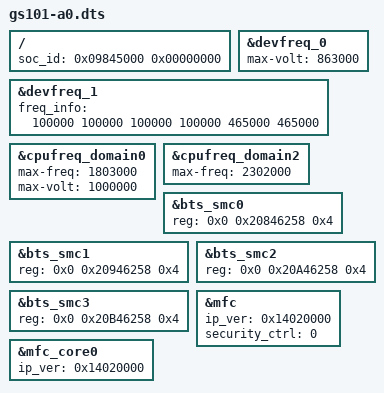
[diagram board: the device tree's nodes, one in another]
// SPDX-License-Identifier: GPL-2.0-only
/*
 * GS101 SoC silicon revisions A0 and A1
 *
 * Copyright 2020 Google LLC
 *
 */

/dts-v1/;
/ {
	/* soc revision info */
	soc_id = <0x09845000 0x00000000>;
};

#include "gs101.dtsi"

&devfreq_0 {
	max-volt = <863000>;
};

&devfreq_1 {
	freq_info = <100000 100000 100000 100000 465000 465000>;
	/* <initial_freq, default_qos, suspend_freq, min, max, reboot_freq> */
};

&cpufreq_domain0 {
	max-freq = <1803000>;
	max-volt = <1000000>;
};
&cpufreq_domain2 {
	max-freq = <2302000>;
};

&bts_smc0 {
	reg = <0x0 0x20846258 0x4>;
};
&bts_smc1 {
	reg = <0x0 0x20946258 0x4>;
};
&bts_smc2 {
	reg = <0x0 0x20A46258 0x4>;
};
&bts_smc3 {
	reg = <0x0 0x20B46258 0x4>;
};

&mfc {
	ip_ver = <0x14020000>;
	/* FW base security ctrl */
	security_ctrl = <0>;
};
&mfc_core0 {
	ip_ver = <0x14020000>;
};
